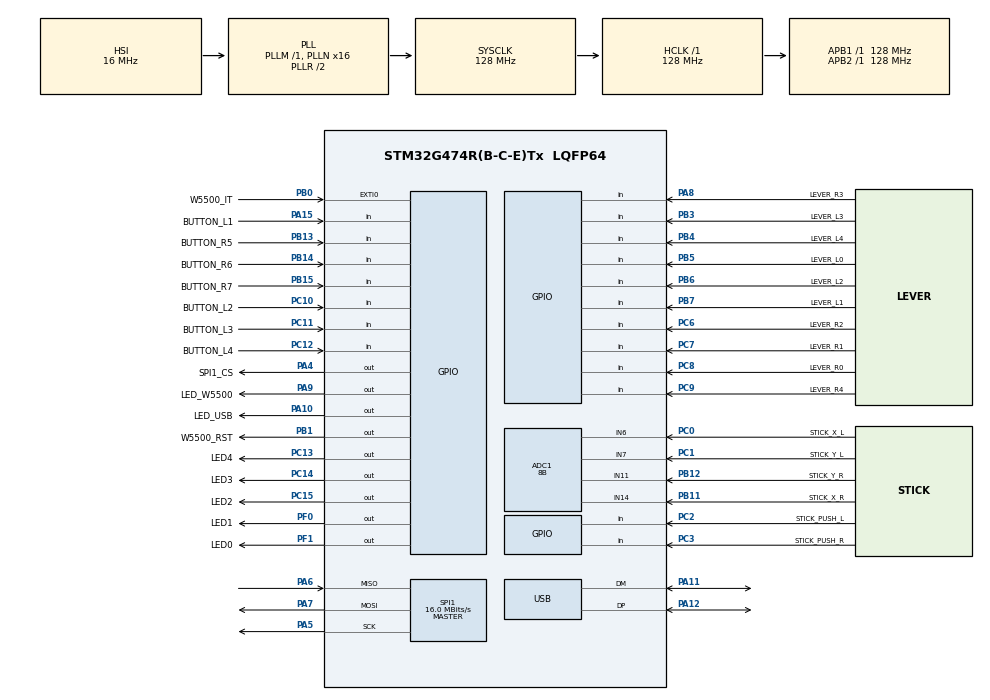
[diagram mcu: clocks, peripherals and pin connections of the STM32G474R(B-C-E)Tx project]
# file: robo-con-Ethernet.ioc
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ADC1.Channel-0\#ChannelRegularConversion=ADC_CHANNEL_6
ADC1.Channel-1\#ChannelRegularConversion=ADC_CHANNEL_7
ADC1.Channel-2\#ChannelRegularConversion=ADC_CHANNEL_11
ADC1.Channel-3\#ChannelRegularConversion=ADC_CHANNEL_14
ADC1.ClockPrescaler=ADC_CLOCK_SYNC_PCLK_DIV4
ADC1.ContinuousConvMode=ENABLE
ADC1.DMAContinuousRequests=ENABLE
ADC1.NbrOfConversion=4
ADC1.NbrOfConversionFlag=1
ADC1.OffsetNumber-0\#ChannelRegularConversion=ADC_OFFSET_NONE
ADC1.OffsetNumber-1\#ChannelRegularConversion=ADC_OFFSET_NONE
ADC1.OffsetNumber-2\#ChannelRegularConversion=ADC_OFFSET_NONE
ADC1.OffsetNumber-3\#ChannelRegularConversion=ADC_OFFSET_NONE
ADC1.Overrun=ADC_OVR_DATA_OVERWRITTEN
ADC1.OversamplingMode=DISABLE
ADC1.Rank-0\#ChannelRegularConversion=1
ADC1.Rank-1\#ChannelRegularConversion=2
ADC1.Rank-2\#ChannelRegularConversion=3
ADC1.Rank-3\#ChannelRegularConversion=4
ADC1.Resolution=ADC_RESOLUTION_8B
ADC1.SamplingTime-0\#ChannelRegularConversion=ADC_SAMPLETIME_47CYCLES_5
ADC1.SamplingTime-1\#ChannelRegularConversion=ADC_SAMPLETIME_47CYCLES_5
ADC1.SamplingTime-2\#ChannelRegularConversion=ADC_SAMPLETIME_47CYCLES_5
ADC1.SamplingTime-3\#ChannelRegularConversion=ADC_SAMPLETIME_47CYCLES_5
ADC1.master=1
Dma.ADC1.0.Direction=DMA_PERIPH_TO_MEMORY
Dma.ADC1.0.EventEnable=DISABLE
Dma.ADC1.0.Instance=DMA1_Channel1
Dma.ADC1.0.MemDataAlignment=DMA_MDATAALIGN_HALFWORD
Dma.ADC1.0.MemInc=DMA_MINC_ENABLE
Dma.ADC1.0.Mode=DMA_CIRCULAR
Dma.ADC1.0.PeriphDataAlignment=DMA_PDATAALIGN_HALFWORD
Dma.ADC1.0.PeriphInc=DMA_PINC_DISABLE
Dma.ADC1.0.Polarity=HAL_DMAMUX_REQ_GEN_RISING
Dma.ADC1.0.Priority=DMA_PRIORITY_LOW
Dma.ADC1.0.RequestNumber=1
Dma.ADC1.0.SignalID=NONE
Dma.ADC1.0.SyncEnable=DISABLE
Dma.ADC1.0.SyncPolarity=HAL_DMAMUX_SYNC_NO_EVENT
Dma.ADC1.0.SyncRequestNumber=1
Dma.ADC1.0.SyncSignalID=NONE
Dma.Request0=ADC1
Mcu.Family=STM32G4
Mcu.Name=STM32G474R(B-C-E)Tx
Mcu.Package=LQFP64
NVIC.DMA1_Channel1_IRQn=true\:4\:0\:true\:false\:true\:false\:true\:true
NVIC.PriorityGroup=NVIC_PRIORITYGROUP_4
NVIC.SPI1_IRQn=true\:3\:0\:true\:false\:true\:true\:true\:true
NVIC.TIM6_DAC_IRQn=true\:2\:0\:true\:false\:true\:true\:true\:true
NVIC.USB_HP_IRQn=true\:6\:0\:true\:false\:true\:true\:true\:true
NVIC.USB_LP_IRQn=true\:7\:0\:true\:false\:true\:true\:true\:true
PA10.GPIO_Label=LED_USB
PA10.Signal=GPIO_Output
PA11.Mode=Device
PA11.Signal=USB_DM
PA12.Mode=Device
PA12.Signal=USB_DP
PA13.Mode=Serial_Wire
PA13.Signal=SYS_JTMS-SWDIO
PA14.Mode=Serial_Wire
PA14.Signal=SYS_JTCK-SWCLK
PA15.GPIO_Label=BUTTON_L1
PA15.GPIO_PuPd=GPIO_PULLDOWN
PA15.Signal=GPIO_Input
PA4.GPIO_Label=SPI1_CS
PA4.GPIO_Speed=GPIO_SPEED_FREQ_HIGH
PA4.PinState=GPIO_PIN_SET
PA4.Signal=GPIO_Output
PA5.Mode=Full_Duplex_Master
PA5.Signal=SPI1_SCK
PA6.Mode=Full_Duplex_Master
PA6.Signal=SPI1_MISO
PA7.Mode=Full_Duplex_Master
PA7.Signal=SPI1_MOSI
PA8.GPIO_Label=LEVER_R3
PA8.Signal=GPIO_Input
PA9.GPIO_Label=LED_W5500
PA9.Signal=GPIO_Output
PB0.GPIO_Label=W5500_IT
PB0.Signal=GPXTI0
PB1.GPIO_Label=W5500_RST
PB1.PinState=GPIO_PIN_SET
PB1.Signal=GPIO_Output
PB11.GPIO_Label=STICK_X_R
PB11.Mode=IN14-Single-Ended
PB11.Signal=ADC1_IN14
PB12.GPIO_Label=STICK_Y_R
PB12.Mode=IN11-Single-Ended
PB12.Signal=ADC1_IN11
PB13.GPIO_Label=BUTTON_R5
PB13.GPIO_PuPd=GPIO_PULLDOWN
PB13.Signal=GPIO_Input
PB14.GPIO_Label=BUTTON_R6
PB14.GPIO_PuPd=GPIO_PULLDOWN
PB14.Signal=GPIO_Input
PB15.GPIO_Label=BUTTON_R7
PB15.GPIO_PuPd=GPIO_PULLDOWN
PB15.Signal=GPIO_Input
PB3.GPIO_Label=LEVER_L3
PB3.Signal=GPIO_Input
PB4.GPIO_Label=LEVER_L4
PB4.Signal=GPIO_Input
PB5.GPIO_Label=LEVER_L0
PB5.Signal=GPIO_Input
PB6.GPIO_Label=LEVER_L2
PB6.Signal=GPIO_Input
PB7.GPIO_Label=LEVER_L1
PB7.Signal=GPIO_Input
PC0.GPIO_Label=STICK_X_L
PC0.Mode=IN6-Single-Ended
PC0.Signal=ADC1_IN6
PC1.GPIO_Label=STICK_Y_L
PC1.Mode=IN7-Single-Ended
PC1.Signal=ADC1_IN7
PC10.GPIO_Label=BUTTON_L2
PC10.GPIO_PuPd=GPIO_PULLDOWN
PC10.Signal=GPIO_Input
PC11.GPIO_Label=BUTTON_L3
PC11.GPIO_PuPd=GPIO_PULLDOWN
PC11.Signal=GPIO_Input
PC12.GPIO_Label=BUTTON_L4
PC12.GPIO_PuPd=GPIO_PULLDOWN
PC12.Signal=GPIO_Input
PC13.GPIO_Label=LED4
PC13.Signal=GPIO_Output
PC14-OSC32_IN.GPIO_Label=LED3
PC14-OSC32_IN.Signal=GPIO_Output
PC15-OSC32_OUT.GPIO_Label=LED2
PC15-OSC32_OUT.Signal=GPIO_Output
PC2.GPIO_Label=STICK_PUSH_L
PC2.Signal=GPIO_Input
PC3.GPIO_Label=STICK_PUSH_R
PC3.Signal=GPIO_Input
PC6.GPIO_Label=LEVER_R2
PC6.Signal=GPIO_Input
PC7.GPIO_Label=LEVER_R1
PC7.Signal=GPIO_Input
PC8.GPIO_Label=LEVER_R0
PC8.Signal=GPIO_Input
PC9.GPIO_Label=LEVER_R4
PC9.Signal=GPIO_Input
PF0-OSC_IN.GPIO_Label=LED1
PF0-OSC_IN.Signal=GPIO_Output
PF1-OSC_OUT.GPIO_Label=LED0
PF1-OSC_OUT.Signal=GPIO_Output
ProjectManager.HeapSize=0x200
ProjectManager.StackSize=0x400
ProjectManager.TargetToolchain=CMake
RCC.ADC12Freq_Value=128000000
RCC.ADC345Freq_Value=128000000
RCC.AHBFreq_Value=128000000
RCC.APB1Freq_Value=128000000
RCC.APB1TimFreq_Value=128000000
RCC.APB2Freq_Value=128000000
RCC.APB2TimFreq_Value=128000000
RCC.CK48CLockSelection=RCC_USBCLKSOURCE_HSI48
RCC.CortexFreq_Value=128000000
RCC.EXTERNAL_CLOCK_VALUE=12288000
RCC.HCLKFreq_Value=128000000
RCC.HSE_VALUE=8000000
RCC.HSI48_VALUE=48000000
RCC.HSI_VALUE=16000000
RCC.LSE_VALUE=32768
RCC.PLLN=16
RCC.SYSCLKFreq_VALUE=128000000
RCC.SYSCLKSource=RCC_SYSCLKSOURCE_PLLCLK
RCC.USART1CLockSelection=RCC_USART1CLKSOURCE_HSI
RCC.USBFreq_Value=48000000
RCC.VCOOutputFreq_Value=256000000
SPI1.BaudRatePrescaler=SPI_BAUDRATEPRESCALER_8
SPI1.CalculateBaudRate=16.0 MBits/s
SPI1.DataSize=SPI_DATASIZE_8BIT
SPI1.Direction=SPI_DIRECTION_2LINES
SPI1.Mode=SPI_MODE_MASTER
SPI1.VirtualType=VM_MASTER
TIM6.PeriodNoDither=9999
TIM6.Prescaler=127
USB_DEVICE.CLASS_NAME_FS=CDC
USB_DEVICE.VirtualMode=Cdc
USB_DEVICE.VirtualModeFS=Cdc_FS
VP_ADC1_TempSens_Input.Mode=IN-TempSens
VP_SYS_VS_DBSignals.Mode=DisableDeadBatterySignals
VP_TIM6_VS_ClockSourceINT.Mode=Enable_Timer
VP_USB_DEVICE_VS_USB_DEVICE_CDC_FS.Mode=CDC_FS
board=custom

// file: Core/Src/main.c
/* USER CODE BEGIN Header */
/**
 ******************************************************************************
 * @file           : main.c
 * @brief          : Main program body
 ******************************************************************************
 * @attention
 *
 * Copyright (c) 2026 STMicroelectronics.
 * All rights reserved.
 *
 * This software is licensed under terms that can be found in the LICENSE file
 * in the root directory of this software component.
 * If no LICENSE file comes with this software, it is provided AS-IS.
 *
 ******************************************************************************
 */
/* USER CODE END Header */
#include "main.h"

#include "adc.h"
#include "dma.h"
#include "gpio.h"
#include "spi.h"
#include "tim.h"
#include "usb_device.h"

/* USER CODE BEGIN Includes */
#include "app/app.hpp"
#include "usbd_cdc_if.h"
/* USER CODE END Includes */

void SystemClock_Config(void);

/* USER CODE BEGIN 0 */
int _write(int file, char* ptr, int len)
{
    if ((CDC_Transmit_FS((uint8_t*)ptr, len) != USBD_OK)) return 0;
    return len;
}
/* USER CODE END 0 */

int main(void)
{

    /* MCU Configuration--------------------------------------------------------*/

    /* Reset of all peripherals, Initializes the Flash interface and the Systick. */
    HAL_Init();

    /* Configure the system clock */
    SystemClock_Config();

    /* Initialize all configured peripherals */
    MX_GPIO_Init();
    MX_DMA_Init();
    MX_ADC1_Init();
    MX_SPI1_Init();
    MX_TIM6_Init();
    MX_USB_Device_Init();
    /* USER CODE BEGIN 2 */
    setup();
    /* USER CODE END 2 */

    /* Infinite loop */
    while (1) {

        /* USER CODE BEGIN 3 */
        loop();
    }
    /* USER CODE END 3 */
}

void SystemClock_Config(void)
{
    RCC_OscInitTypeDef RCC_OscInitStruct = {0};
    RCC_ClkInitTypeDef RCC_ClkInitStruct = {0};

    /** Configure the main internal regulator output voltage
     */
    HAL_PWREx_ControlVoltageScaling(PWR_REGULATOR_VOLTAGE_SCALE1);

    /** Initializes the RCC Oscillators according to the specified parameters
     * in the RCC_OscInitTypeDef structure.
     */
    RCC_OscInitStruct.OscillatorType      = RCC_OSCILLATORTYPE_HSI | RCC_OSCILLATORTYPE_HSI48;
    RCC_OscInitStruct.HSIState            = RCC_HSI_ON;
    RCC_OscInitStruct.HSICalibrationValue = RCC_HSICALIBRATION_DEFAULT;
    RCC_OscInitStruct.HSI48State          = RCC_HSI48_ON;
    RCC_OscInitStruct.PLL.PLLState        = RCC_PLL_ON;
    RCC_OscInitStruct.PLL.PLLSource       = RCC_PLLSOURCE_HSI;
    RCC_OscInitStruct.PLL.PLLM            = RCC_PLLM_DIV1;
    RCC_OscInitStruct.PLL.PLLN            = 16;
    RCC_OscInitStruct.PLL.PLLP            = RCC_PLLP_DIV2;
    RCC_OscInitStruct.PLL.PLLQ            = RCC_PLLQ_DIV2;
    RCC_OscInitStruct.PLL.PLLR            = RCC_PLLR_DIV2;
    if (HAL_RCC_OscConfig(&RCC_OscInitStruct) != HAL_OK) {
        Error_Handler();
    }

    /** Initializes the CPU, AHB and APB buses clocks
     */
    RCC_ClkInitStruct.ClockType =
        RCC_CLOCKTYPE_HCLK | RCC_CLOCKTYPE_SYSCLK | RCC_CLOCKTYPE_PCLK1 | RCC_CLOCKTYPE_PCLK2;
    RCC_ClkInitStruct.SYSCLKSource   = RCC_SYSCLKSOURCE_PLLCLK;
    RCC_ClkInitStruct.AHBCLKDivider  = RCC_SYSCLK_DIV1;
    RCC_ClkInitStruct.APB1CLKDivider = RCC_HCLK_DIV1;
    RCC_ClkInitStruct.APB2CLKDivider = RCC_HCLK_DIV1;

    if (HAL_RCC_ClockConfig(&RCC_ClkInitStruct, FLASH_LATENCY_4) != HAL_OK) {
        Error_Handler();
    }
}

void Error_Handler(void)
{
    /* USER CODE BEGIN Error_Handler_Debug */
    /* User can add his own implementation to report the HAL error return state */
    __disable_irq();
    HAL_GPIO_WritePin(LED0_GPIO_Port, LED0_Pin, GPIO_PIN_SET);
    while (1) {
    }
    /* USER CODE END Error_Handler_Debug */
}
